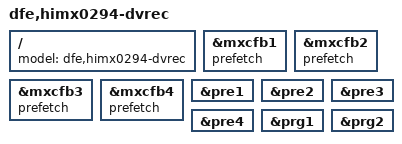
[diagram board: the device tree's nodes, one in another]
/*
 * Copyright 2015 DResearch Fahrzeugelektronik GmbH
 * Copyright 2013 Boundary Devices
 * Copyright 2012 Freescale Semiconductor, Inc.
 * Copyright 2011 Linaro Ltd.
 *
 * The code contained herein is licensed under the GNU General Public
 * License. You may obtain a copy of the GNU General Public License
 * Version 2 or later at the following locations:
 *
 * http://www.opensource.org/licenses/gpl-license.html
 * http://www.gnu.org/copyleft/gpl.html
 */

#include "imx6q-himx0294-dvrec.dts"
#include "imx6qp.dtsi"

/ {
	model = "dfe,himx0294-dvrec";
};

&mxcfb1 {
	prefetch;
};

&mxcfb2 {
	prefetch;
};

&mxcfb3 {
	prefetch;
};

&mxcfb4 {
	prefetch;
};

&pre1 {
	status = "okay";
};

&pre2 {
	status = "okay";
};

&pre3 {
	status = "okay";
};

&pre4 {
	status = "okay";
};

&prg1 {
	status = "okay";
};

&prg2 {
	status = "okay";
};

